# STM32F302C6T6 register map
File version: 1.0
Registers are 32-bit, access not given, reset 0x0 unless marked. A register's access mark holds for its fields unless they carry their own. Offsets are from the block's base; [hi:lo] are bit positions; {n}, {i} and the like mark numbered series.

## EXTI
Base 0x40010400
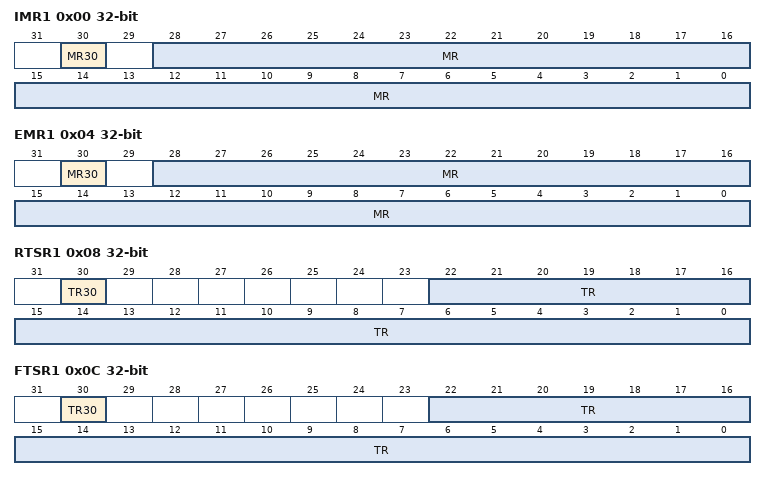
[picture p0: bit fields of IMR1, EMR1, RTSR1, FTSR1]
0x00 IMR1
  [30] MR30, [28:0] MR
0x04 EMR1
  [30] MR30, [28:0] MR
0x08 RTSR1
  [30] TR30, [22:0] TR
0x0C FTSR1
  [30] TR30, [22:0] TR
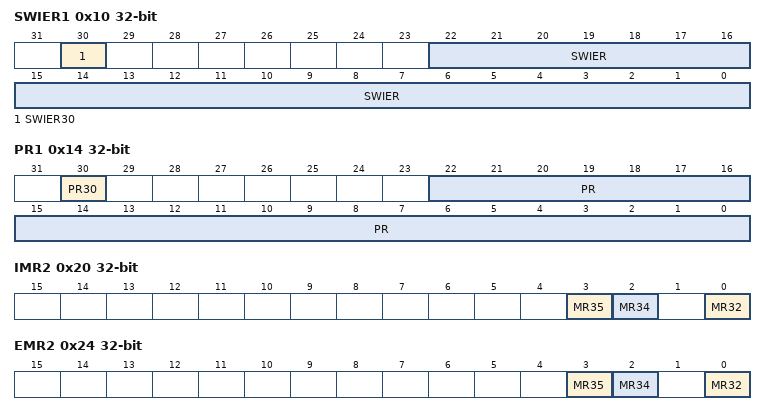
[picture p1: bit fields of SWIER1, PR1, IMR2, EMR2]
0x10 SWIER1
  [30] SWIER30, [22:0] SWIER
0x14 PR1
  [30] PR30, [22:0] PR
0x20 IMR2
  [3] MR35, [2] MR34, [0] MR32
0x24 EMR2
  [3] MR35, [2] MR34, [0] MR32
0x28 RTSR2
  [0] TR32
0x2C FTSR2
  [0] TR32
0x30 SWIER2
  [0] SWIER32
0x34 PR2
  [0] PR32

## TIM1
Base 0x40012C00
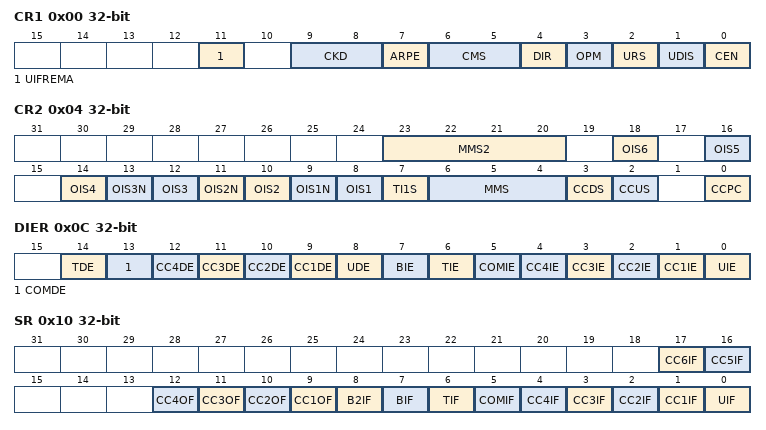
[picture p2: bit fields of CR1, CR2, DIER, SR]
0x00 CR1
  [11] UIFREMA, [9:8] CKD, [7] ARPE, [6:5] CMS, [4] DIR, [3] OPM, [2] URS, [1] UDIS, [0] CEN
0x04 CR2
  [23:20] MMS2, [2n+6] OIS{n} (n=1..6), [13] OIS3N, [11] OIS2N, [9] OIS1N, [7] TI1S, [6:4] MMS, [3] CCDS, [2] CCUS, [0] CCPC
0x08 SMCR
  [15] ETP, [14] ECE, [13:12] ETPS, [11:8] ETF, [7] MSM, [6:4] TS, [3] OCCS, [16:0] SMS
0x0C DIER
  [14] TDE, [13] COMDE, [n+8] CC{n}DE (n=1..4), [8] UDE, [7] BIE, [6] TIE, [5] COMIE, [n] CC{n}IE (n=1..4), [0] UIE
0x10 SR
  [17] CC6IF, [16] CC5IF, [n+8] CC{n}OF (n=1..4), [8] B2IF, [7] BIF, [6] TIF, [5] COMIF, [n] CC{n}IF (n=1..4), [0] UIF
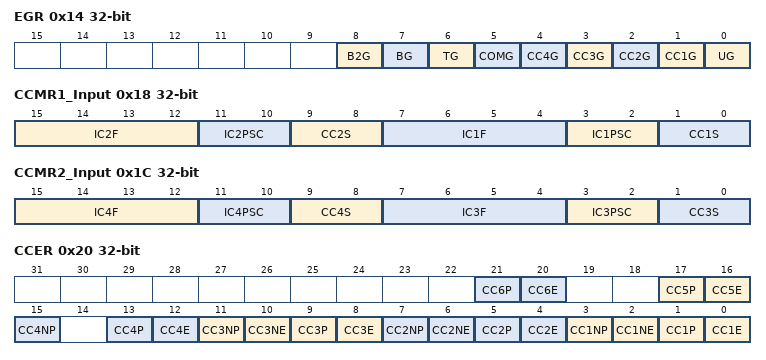
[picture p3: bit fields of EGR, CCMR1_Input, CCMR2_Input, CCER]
0x14 EGR
  [8] B2G, [7] BG, [6] TG, [5] COMG, [n] CC{n}G (n=1..4), [0] UG
0x18 CCMR1_Input
  [15:12] IC2F, [11:10] IC2PSC, [9:8] CC2S, [7:4] IC1F, [3:2] IC1PSC, [1:0] CC1S
0x18 CCMR1_Output
  [15] OC2CE, [24:12] OC2M, [11] OC2PE, [10] OC2FE, [9:8] CC2S, [7] OC1CE, [16:4] OC1M, [3] OC1PE, [2] OC1FE, [1:0] CC1S
0x1C CCMR2_Input
  [15:12] IC4F, [11:10] IC4PSC, [9:8] CC4S, [7:4] IC3F, [3:2] IC3PSC, [1:0] CC3S
0x1C CCMR2_Output
  [15] OC4CE, [24:12] OC4M, [11] OC4PE, [10] OC4FE, [9:8] CC4S, [7] OC3CE, [16:4] OC3M, [3] OC3PE, [2] OC3FE, [1:0] CC3S
0x20 CCER
  [4n-3] CC{n}P (n=1..6), [4n-4] CC{n}E (n=1..6), [4n-1] CC{n}NP (n=1..4), [10] CC3NE, [6] CC2NE, [2] CC1NE
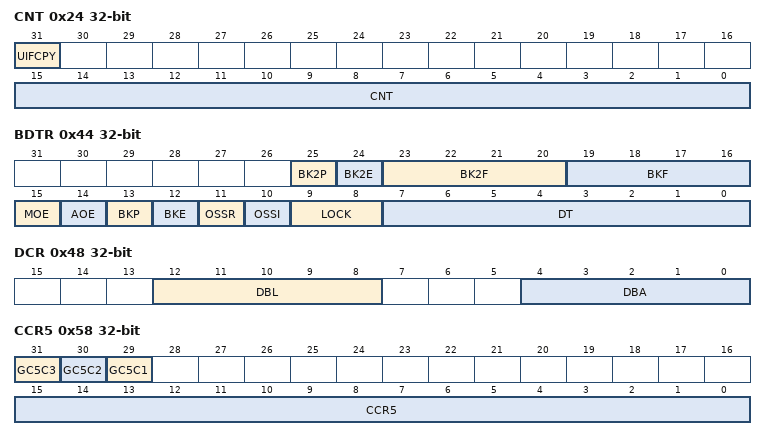
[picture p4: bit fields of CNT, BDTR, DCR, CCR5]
0x24 CNT
  [31] UIFCPY, [15:0] CNT
0x28 PSC
  [15:0] PSC
0x2C ARR
  [15:0] ARR
0x30 RCR
  [15:0] REP
{0x30+4i} CCR{i} (i=1..4)
  [15:0] CCR{i}
0x44 BDTR
  [25] BK2P, [24] BK2E, [23:20] BK2F, [19:16] BKF, [15] MOE, [14] AOE, [13] BKP, [12] BKE, [11] OSSR, [10] OSSI, [9:8] LOCK, [7:0] DT
0x48 DCR
  [12:8] DBL, [4:0] DBA
0x4C DMAR
  [31:0] DMAB
0x50 OR
  [1:0] TIM1_ETR_ADC1_RMP
0x54 CCMR3_Output
  [15] OC6CE, [24:12] OC6M, [11] OC6PE, [10] OC6FE, [7] OC5CE, [16:4] OC5M, [3] OC5PE, [2] OC5FE
0x58 CCR5
  [31] GC5C3, [30] GC5C2, [29] GC5C1, [15:0] CCR5
0x5C CCR6
  [15:0] CCR6

## TIM15
Base 0x40014000
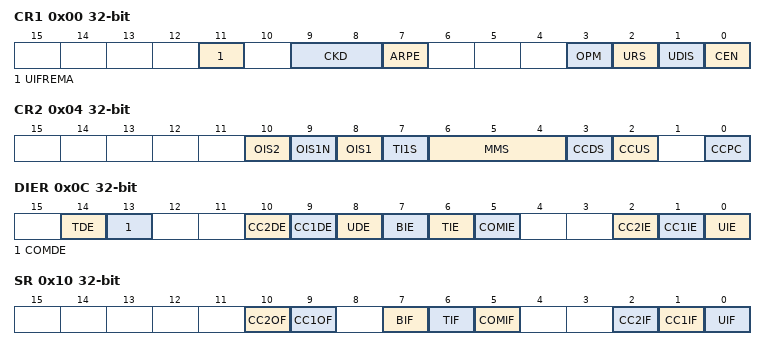
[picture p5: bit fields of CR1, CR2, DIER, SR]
0x00 CR1
  [11] UIFREMA, [9:8] CKD, [7] ARPE, [3] OPM, [2] URS, [1] UDIS, [0] CEN
0x04 CR2
  [10] OIS2, [9] OIS1N, [8] OIS1, [7] TI1S, [6:4] MMS, [3] CCDS, [2] CCUS, [0] CCPC
0x08 SMCR
  [7] MSM, [6:4] TS, [16:0] SMS
0x0C DIER
  [14] TDE, [13] COMDE, [10] CC2DE, [9] CC1DE, [8] UDE, [7] BIE, [6] TIE, [5] COMIE, [2] CC2IE, [1] CC1IE, [0] UIE
0x10 SR
  [10] CC2OF, [9] CC1OF, [7] BIF, [6] TIF, [5] COMIF, [2] CC2IF, [1] CC1IF, [0] UIF
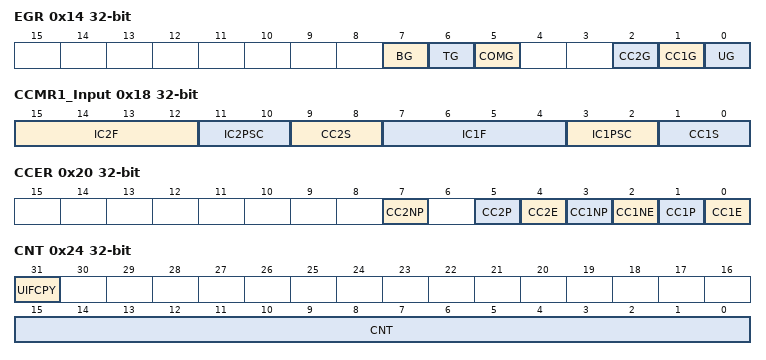
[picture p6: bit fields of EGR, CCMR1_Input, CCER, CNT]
0x14 EGR
  [7] BG, [6] TG, [5] COMG, [2] CC2G, [1] CC1G, [0] UG
0x18 CCMR1_Output
  [15] OC2CE, [24:12] OC2M, [11] OC2PE, [10] OC2FE, [9:8] CC2S, [7] OC!CE, [16:4] OC1M, [3] OC1PE, [2] OC1FE, [1:0] CC1S
0x18 CCMR1_Input
  [15:12] IC2F, [11:10] IC2PSC, [9:8] CC2S, [7:4] IC1F, [3:2] IC1PSC, [1:0] CC1S
0x20 CCER
  [7] CC2NP, [5] CC2P, [4] CC2E, [3] CC1NP, [2] CC1NE, [1] CC1P, [0] CC1E
0x24 CNT
  [31] UIFCPY, [15:0] CNT
0x28 PSC
  [15:0] PSC
0x2C ARR
  [15:0] ARR
0x30 RCR
  [7:0] REP
0x34 CCR1
  [15:0] CCR1
0x38 CCR2
  [15:0] CCR2
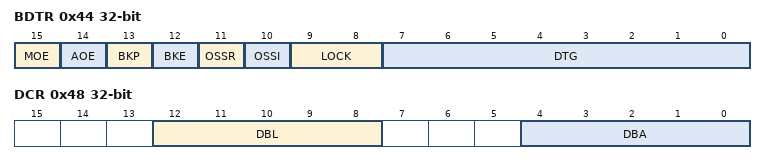
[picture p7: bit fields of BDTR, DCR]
0x44 BDTR
  [15] MOE, [14] AOE, [13] BKP, [12] BKE, [11] OSSR, [10] OSSI, [9:8] LOCK, [7:0] DTG
0x48 DCR
  [12:8] DBL, [4:0] DBA
0x4C DMAR
  [15:0] DMAB

## TIM16
Base 0x40014400
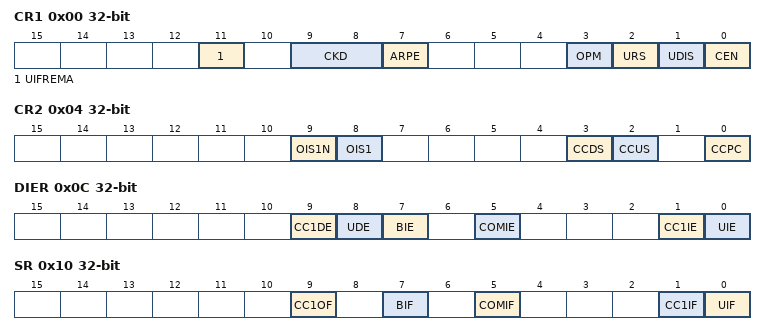
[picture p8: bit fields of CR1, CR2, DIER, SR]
0x00 CR1
  [11] UIFREMA, [9:8] CKD, [7] ARPE, [3] OPM, [2] URS, [1] UDIS, [0] CEN
0x04 CR2
  [9] OIS1N, [8] OIS1, [3] CCDS, [2] CCUS, [0] CCPC
0x0C DIER
  [9] CC1DE, [8] UDE, [7] BIE, [5] COMIE, [1] CC1IE, [0] UIE
0x10 SR
  [9] CC1OF, [7] BIF, [5] COMIF, [1] CC1IF, [0] UIF
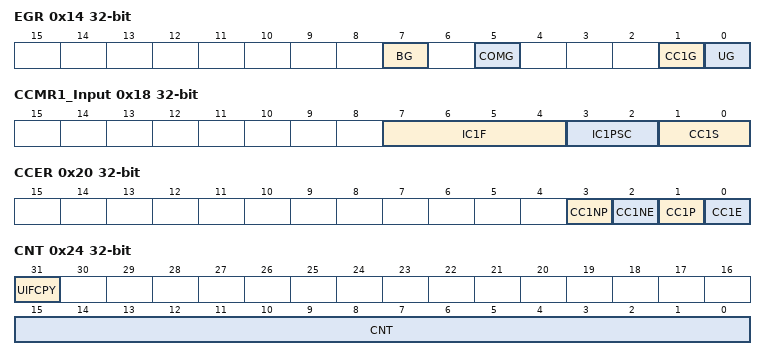
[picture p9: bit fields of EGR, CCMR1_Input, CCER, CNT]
0x14 EGR
  [7] BG, [5] COMG, [1] CC1G, [0] UG
0x18 CCMR1_Output
  [7] OC1CE, [16:4] OC1M, [3] OC1PE, [2] OC1FE, [1:0] CC1S
0x18 CCMR1_Input
  [7:4] IC1F, [3:2] IC1PSC, [1:0] CC1S
0x20 CCER
  [3] CC1NP, [2] CC1NE, [1] CC1P, [0] CC1E
0x24 CNT
  [31] UIFCPY, [15:0] CNT
0x28 PSC
  [15:0] PSC
0x2C ARR
  [15:0] ARR
0x30 RCR
  [7:0] REP
0x34 CCR1
  [15:0] CCR1
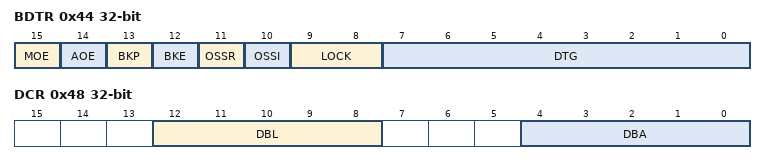
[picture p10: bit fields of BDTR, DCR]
0x44 BDTR
  [15] MOE, [14] AOE, [13] BKP, [12] BKE, [11] OSSR, [10] OSSI, [9:8] LOCK, [7:0] DTG
0x48 DCR
  [12:8] DBL, [4:0] DBA
0x4C DMAR
  [15:0] DMAB
0x50 OR
  [1:0] TI1_RMP

## TIM17
Base 0x40014800
Registers as TIM16, without OR.
